# AE402FA0E5597BE0_CM55_HP_View register map
Vendor: Alif Semiconductor; Series: E4; File version: 1.0
CPU: CM55 r1p0, selectable endian, MPU, FPU, double-precision FPU, DSP, VTOR, 8 interrupt priority bits, 1 SAU regions
Registers are 32-bit, read-write, reset 0x0 unless marked. A register's access mark holds for its fields unless they carry their own. Offsets are from the block's base; [hi:lo] are bit positions; {n}, {i} and the like mark numbered series.

## JPEG
Base 0x49044000
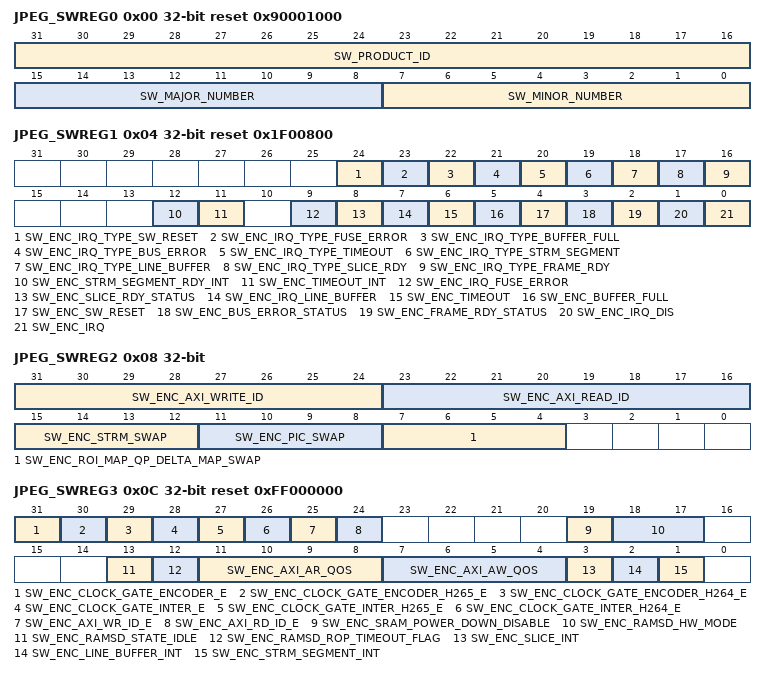
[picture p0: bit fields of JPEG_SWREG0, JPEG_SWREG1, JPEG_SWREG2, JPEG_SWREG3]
0x00 JPEG_SWREG0 ro reset 0x90001000 — swreg0 register
  [31:16] SW_PRODUCT_ID — Product ID
  [15:8] SW_MAJOR_NUMBER — Major number
  [7:0] SW_MINOR_NUMBER — Minor number
0x04 JPEG_SWREG1 reset 0x1F00800 — swreg1 register
  [24] SW_ENC_IRQ_TYPE_SW_RESET — Irq type sw reset mask.0=normal interruption. 1=abnormal interruption
  [23] SW_ENC_IRQ_TYPE_FUSE_ERROR — Irq type fuse error mask.0=normal interruption. 1=abnormal interruption
  [22] SW_ENC_IRQ_TYPE_BUFFER_FULL — Irq type fuse buffer full mask.0=normal interruption. 1=abnormal interruption
  [21] SW_ENC_IRQ_TYPE_BUS_ERROR — Irq type bus error mask.0=normal interruption. 1=abnormal interruption
  [20] SW_ENC_IRQ_TYPE_TIMEOUT — Irq type timeout mask. 0=normal interruption. 1=abnormal interruption
  [19] SW_ENC_IRQ_TYPE_STRM_SEGMENT — Irq type stream segment mask. 0=normal interruption. 1=abnormal interruption.
  [18] SW_ENC_IRQ_TYPE_LINE_BUFFER — Irq type line buffer mask. 0=normal interruption. 1=abnormal interruption.
  [17] SW_ENC_IRQ_TYPE_SLICE_RDY — Irq type slice ready mask. 0=normal interruption. 1=abnormal interruption.
  [16] SW_ENC_IRQ_TYPE_FRAME_RDY — Irq type frame ready mask. 0=normal interruption. 1=abnormal interruption.
  [12] SW_ENC_STRM_SEGMENT_RDY_INT — Output stream segment IRQ. When high stream segment requests an interrupt. SW will reset this after interrupt is handled. It is clear by writing 1.
  [11] SW_ENC_TIMEOUT_INT — enable timeout interrupt when 1
  [9] SW_ENC_IRQ_FUSE_ERROR — Interrupt Interrupt status bit encoder. When this bit is high encoder has a FUSE error. SW try to setup feature but HW miss the feature set. It is clear by writing 1.
  [8] SW_ENC_SLICE_RDY_STATUS — Interrupt status bit encoder. When this bit is high encoder has encoded a slice. It is clear by writing 1.
  [7] SW_ENC_IRQ_LINE_BUFFER — Interrupt status bit encoder linebuffer empty. When setting. Encoder has finished encoding input buffers. It is clear by writing 1.
  [6] SW_ENC_TIMEOUT — Interrupt status bit encoder timeout. When high the encoder has been idling for too long. Possible only if timeout interrupt is enabled. It is clear by writing 1.
  [5] SW_ENC_BUFFER_FULL — IRQ buffer full status bit. bufferFullInterrupt. It is clear by writing 1.
  [4] SW_ENC_SW_RESET — IRQ SW reset status bit. It is clear by writing 1.
  [3] SW_ENC_BUS_ERROR_STATUS — Interrupt status bit bus. Error response from bus. It is clear by writing 1.
  [2] SW_ENC_FRAME_RDY_STATUS — Interrupt status bit encoder. When this bit is high encoder has encoded a picture. It is clear by writing 1.
  [1] SW_ENC_IRQ_DIS — Encoder IRQ disable. When high there are no interrupts concerning encoder from HW. Polling must be used to see the interrupt statuses.
  [0] SW_ENC_IRQ — Encoder IRQ. When high encoder requests an interrupt. SW will reset this after interrupt is handled. It is clear by writing 1.
0x08 JPEG_SWREG2 — swreg2 register
  [31:24] SW_ENC_AXI_WRITE_ID — AXI Write ID
  [23:16] SW_ENC_AXI_READ_ID — AXI Read ID
  [15:12] SW_ENC_STRM_SWAP — byte swap config for output stream data.4 Bit byte order vector to control byte locations inside HW internal 128 bit data vector. For 64 and 32 bit external bus widths the data is first gathered to 128 bit width and then bytes swapped accordingly
  [11:8] SW_ENC_PIC_SWAP — Byte swap configuration for picture data (encoder input)
  [7:4] SW_ENC_ROI_MAP_QP_DELTA_MAP_SWAP — Byte swap configuration for qp delta of ROI map (include jpeg roimap)
0x0C JPEG_SWREG3 reset 0xFF000000 — swreg3 register
  [31] SW_ENC_CLOCK_GATE_ENCODER_E — ASIC encoder clock gating control. 0=clock always on. 1=hardware clock gating control
  [30] SW_ENC_CLOCK_GATE_ENCODER_H265_E — ASIC encoder clock gating control for h265. 0=clock always on. 1=hardware clock gating control
  [29] SW_ENC_CLOCK_GATE_ENCODER_H264_E — ASIC encoder clock gating control for h264. 0=clock always on. 1=hardware clock gating control
  [28] SW_ENC_CLOCK_GATE_INTER_E — ASIC inter clock gating control. 0=clock always on. 1=hardware clock gating control
  [27] SW_ENC_CLOCK_GATE_INTER_H265_E — ASIC inter clock gating control for h265. 0=clock always on. 1=hardware clock gating control
  [26] SW_ENC_CLOCK_GATE_INTER_H264_E — ASIC inter clock gating control for h264. 0=clock always on. 1=hardware clock gating control
  [25] SW_ENC_AXI_WR_ID_E — axi write enable 0=disable. 1=enable.
  [24] SW_ENC_AXI_RD_ID_E — axi read enable 0=disable. 1=enable.
  [19] SW_ENC_SRAM_POWER_DOWN_DISABLE — SRAM power down mode disable
    1=SRAM power always on; 0=go into power down mode when clock is gated
  [18:17] SW_ENC_RAMSD_HW_MODE — SRAM SD HW controlled mode
  [13] SW_ENC_RAMSD_STATE_IDLE ro — SRAM SD process idle state 0=some srams are in the sd process. 1=all sram have completed sd process
  [12] SW_ENC_RAMSD_ROP_TIMEOUT_FLAG — Flags the timeout status of the sram SD_ROP signal.0=the sram SD_ROP signal has not timed out.1=the sram SD_ROP signal has timed out
  [11:8] SW_ENC_AXI_AR_QOS — AXI Qos identifier sent on the read address channel for read transaction
  [7:4] SW_ENC_AXI_AW_QOS — AXI Qos identifier sent on the write address channel for write transaction
  [3] SW_ENC_SLICE_INT — enable slice interrupt when 1
  [2] SW_ENC_LINE_BUFFER_INT — enable line buffer interrupt when 1
  [1] SW_ENC_STRM_SEGMENT_INT — enable stream segment interrupt when 1
0x10 JPEG_SWREG4 — swreg4 register
  [31:29] SW_ENC_MODE — Encoding mode. streamType.1=hevc. 2=h264. 3=av1. 4=jpeg. 5=Reserved. 6=cutree. 7=vp9
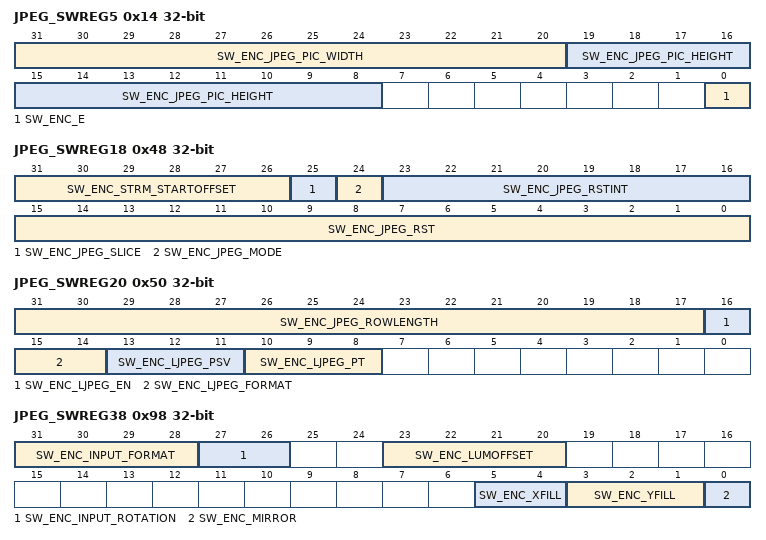
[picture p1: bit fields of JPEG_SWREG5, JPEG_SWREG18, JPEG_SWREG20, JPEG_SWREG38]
0x14 JPEG_SWREG5 — swreg5 register
  [31:20] SW_ENC_JPEG_PIC_WIDTH — Encoded jpeg width. jpgLumWidth(unit 8 pixels)
  [19:8] SW_ENC_JPEG_PIC_HEIGHT — Encoded jpeg height. jpgLumHeight(unit 8 pixels):Max width x height is 16384 x 16384
  [0] SW_ENC_E — encoder enable. Setting this bit high will start the encoding operation. HW will reset this when picture is processed or bus error or timeout interrupt is given.
0x20 JPEG_SWREG8 — swreg8 register
  [31:0] SW_ENC_OUTPUT_STRM_BASE — stream output buffer0 base address
0x24 JPEG_SWREG9 — swreg9 register
  [31:0] SW_ENC_OUTPUT_STRM_BUFFER_LIMIT — Stream buffer0 limit / Output stream size (bytes). If buffer0 limit is reached and sw_enc_HWStreamBufChain=0 buffer_full_IRQ will be generated. Output stream size will be updated here when a slice or frame is finished
0x30 JPEG_SWREG12 — swreg12 register
  [31:0] SW_ENC_INPUT_Y_BASE — input image lum base address
0x34 JPEG_SWREG13 — swreg13 register
  [31:0] SW_ENC_INPUT_CB_BASE — input image cb base address
0x38 JPEG_SWREG14 — swreg14 register
  [31:0] SW_ENC_INPUT_CR_BASE — input image cr base address
0x48 JPEG_SWREG18 — swreg18 register
  [31:26] SW_ENC_STRM_STARTOFFSET — Stream start offset = amount of StrmHdrRem (bits) [0..63]
  [25] SW_ENC_JPEG_SLICE — JPEG slice enable. 0=picture ends with EOI. 1=slice ends with RST
  [24] SW_ENC_JPEG_MODE — JPEG mode. 0=4:2:0 (4lum+2chr blocks/MCU). 1=4:2:2 (2lum+2chr blocks/MCU)
  [23:16] SW_ENC_JPEG_RSTINT — JPEG restart marker interval when slices are disabled (mb rows) [0..255]
  [15:0] SW_ENC_JPEG_RST — JPEG restart marker for first RST. incremented by HW for next RST
0x4C JPEG_SWREG19 — swreg19 register
  [31:0] SW_ENC_STRM_HDRREM1 — Stream header remainder bits MSB (MSB aligned)
0x50 JPEG_SWREG20 — swreg20 register
  [31:17] SW_ENC_JPEG_ROWLENGTH — JPEG Input luminance row length. jpgLumWidthSrc (pixels) [96..16384]
  [16] SW_ENC_LJPEG_EN — JPEG enable lossless JPEG with Huffman coding
  [15:14] SW_ENC_LJPEG_FORMAT — JPEG CodingMode 0:420 1:422 2:lumaonly
  [13:11] SW_ENC_LJPEG_PSV — JPEG prediction selection value for lossless
  [10:8] SW_ENC_LJPEG_PT — JPEG point transform value for lossless
0x54 JPEG_SWREG21 — swreg21 register
  [31:0] SW_ENC_STRM_HDRREM2 — Stream header remainder bits LSB (MSB aligned)
0x94 JPEG_SWREG37 — swreg37 register
  [3:0] SW_ENC_CHROFFSET — Input chrominance offset (bytes) [0..15]
0x98 JPEG_SWREG38 — swreg38 register
  [31:28] SW_ENC_INPUT_FORMAT — Input image format. inputFormat. 0=YUV420P/1=YUV420SP/2=YUYV422/3=UYVY422/4=RGB565/5=RGB555/6=RGB444/7=RGB888/8=RGB101010/9=I010/10=P010/11=PACKED10BITPLANAR/12=Y0L2/13=TILE32/14=TILE16PCK4
  [27:26] SW_ENC_INPUT_ROTATION — Input image rotation. 0=disabled. 1=90 degrees right. 2=90 degrees left.3=180 degree right.
  [23:20] SW_ENC_LUMOFFSET — Input luminance offset (bytes) [0..15]
  [5:4] SW_ENC_XFILL — Overfill pixels on right edge of image div2 [0.1.2.3]
  [3:1] SW_ENC_YFILL — Overfill pixels on bottom edge of image. YFill. [0...7]
  [0] SW_ENC_MIRROR — mirror or not. [0.1]
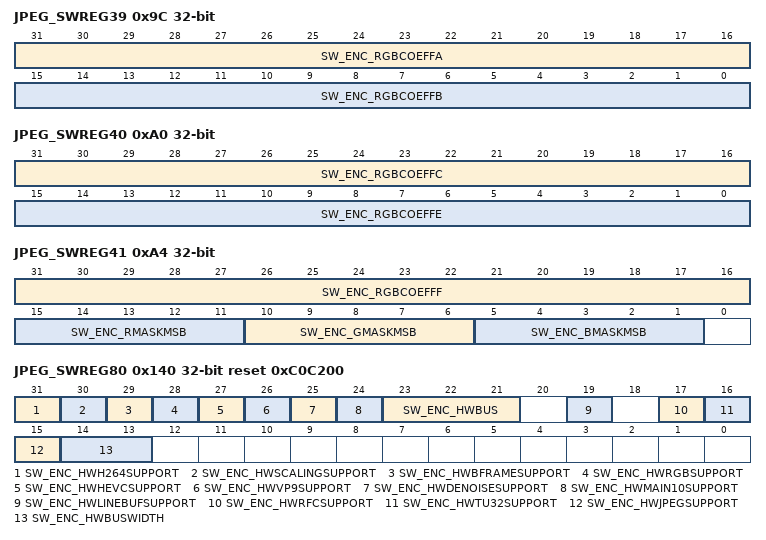
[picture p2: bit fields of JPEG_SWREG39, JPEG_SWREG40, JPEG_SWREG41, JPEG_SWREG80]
0x9C JPEG_SWREG39 — swreg39 register
  [31:16] SW_ENC_RGBCOEFFA — RGB to YUV conversion coefficient A
  [15:0] SW_ENC_RGBCOEFFB — RGB to YUV conversion coefficient B
0xA0 JPEG_SWREG40 — swreg40 register
  [31:16] SW_ENC_RGBCOEFFC — RGB to YUV conversion coefficient C
  [15:0] SW_ENC_RGBCOEFFE — RGB to YUV conversion coefficient D
0xA4 JPEG_SWREG41 — swreg41 register
  [31:16] SW_ENC_RGBCOEFFF — RGB to YUV conversion coefficient E
  [15:11] SW_ENC_RMASKMSB — RGB R-component mask MSB bit position [0..31]
  [10:6] SW_ENC_GMASKMSB — RGB G-component mask MSB bit position [0..31]
  [5:1] SW_ENC_BMASKMSB — RGB B-component mask MSB bit position [0..31]
0xB0 JPEG_SWREG44 — swreg44 register
  [1:0] SW_ENC_INPUT_FORMAT_MSB — Input image format bit[5:4]. inputFormatMsb.
0xB4 JPEG_SWREG45 — swreg45 register
  [27] SW_ENC_CHROMA_SWAP — Swap order of chroma bytes in semiplanar input format.
0xD4 JPEG_SWREG53 — swreg53 register
  [31:0] SW_ENC_INPUT_Y_BASE_MSB — input lum base address MSB
0xD8 JPEG_SWREG54 — swreg54 register
  [31:0] SW_ENC_INPUT_CB_BASE_MSB — input cb base address MSB
0xDC JPEG_SWREG55 — swreg55 register
  [31:0] SW_ENC_INPUT_CR_BASE_MSB — input cr base address MSB
0xEC JPEG_SWREG59 — swreg59 register
  [31:0] SW_ENC_OUTPUT_STRM_BASE_MSB — stream output buffer0 address MSB
0x140 JPEG_SWREG80 ro reset 0xC0C200 — swreg80 register
  [31] SW_ENC_HWH264SUPPORT — H264 encoding supported by HW. 0=not supported. 1=supported
  [30] SW_ENC_HWSCALINGSUPPORT — Down-scaling supported by HW. 0=not supported. 1=supported
  [29] SW_ENC_HWBFRAMESUPPORT — HW bframe support. 0=not support bframe. 1=support bframe
  [28] SW_ENC_HWRGBSUPPORT — RGB to YUV conversion supported by HW. 0=not supported. 1=supported
  [27] SW_ENC_HWHEVCSUPPORT — HEVC encoding supported by HW. 0=not supported. 1=supported
  [26] SW_ENC_HWVP9SUPPORT — VP9 encoding supported by HW. 0=not supported. 1=supported
  [25] SW_ENC_HWDENOISESUPPORT — denoise supported by HW. 0=not supported. 1=supported
  [24] SW_ENC_HWMAIN10SUPPORT — main10 supported by HW. 0=main8 supported. 1=main10 supported
  [23:21] SW_ENC_HWBUS — Bus connection of HW. 1=AHB. 2=OCP. 3=AXI. 4=PCI. 5=AXIAHB. 6=AXIAPB.
  [19] SW_ENC_HWLINEBUFSUPPORT — LineBuffer input mode supported by HW. 0=not supported. 1=supported
  [17] SW_ENC_HWRFCSUPPORT — Reference frame compression supported by HW. 0=not supported. 1=supported
  [16] SW_ENC_HWTU32SUPPORT — TU32 supported by HW. 0=not supported. 1=supported
  [15] SW_ENC_HWJPEGSUPPORT — JPEG encoder supported by HW. 0=not supported. 1=supported
  [14:13] SW_ENC_HWBUSWIDTH — Bus width of HW. 0=32b. 1=64b. 2=128b
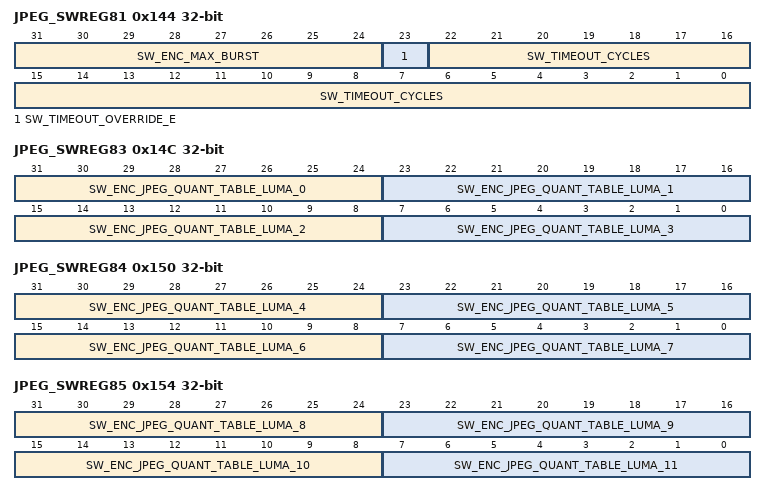
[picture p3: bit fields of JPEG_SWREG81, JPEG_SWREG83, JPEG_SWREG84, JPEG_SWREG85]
0x144 JPEG_SWREG81 — swreg81 register
  [31:24] SW_ENC_MAX_BURST — Maximum AXI burst length.Default value 0x10
  [23] SW_TIMEOUT_OVERRIDE_E — enable signal if timeout period is controlled by software Default value: 0x0
  [22:0] SW_TIMEOUT_CYCLES — timeout cycles number default value: 0x0
0x148 JPEG_SWREG82 — swreg82 register
  [31:0] SW_ENC_HW_PERFORMANCE — record hardware performance(cycles) of current picture
0x14C JPEG_SWREG83 — swreg83 register
  [31-8n:24-8n] SW_ENC_JPEG_QUANT_TABLE_LUMA_{n} (n=0..3) — jpeg quant table luma entry {n}
0x150 JPEG_SWREG84 — swreg84 register
  [63-8n:56-8n] SW_ENC_JPEG_QUANT_TABLE_LUMA_{n} (n=4..7) — jpeg quant table luma entry {n}
0x154 JPEG_SWREG85 — swreg85 register
  [95-8n:88-8n] SW_ENC_JPEG_QUANT_TABLE_LUMA_{n} (n=8..11) — jpeg quant table luma entry {n}
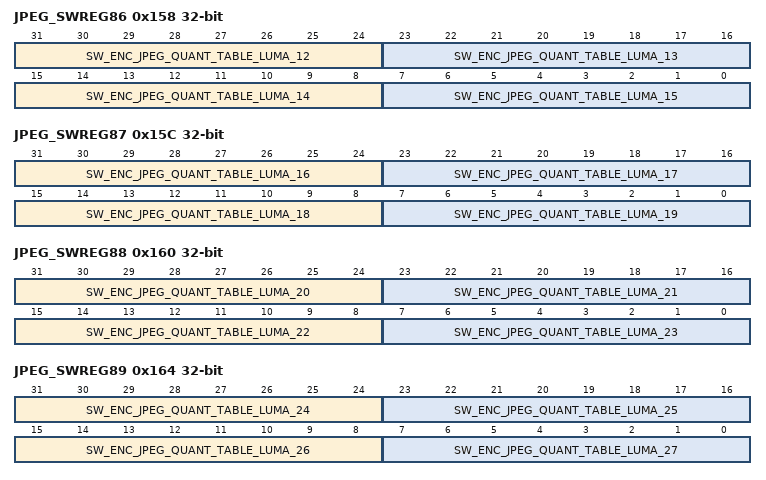
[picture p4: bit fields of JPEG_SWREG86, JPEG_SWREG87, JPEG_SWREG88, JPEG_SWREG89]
0x158 JPEG_SWREG86 — swreg86 register
  [127-8n:120-8n] SW_ENC_JPEG_QUANT_TABLE_LUMA_{n} (n=12..15) — jpeg quant table luma entry {n}
0x15C JPEG_SWREG87 — swreg87 register
  [159-8n:152-8n] SW_ENC_JPEG_QUANT_TABLE_LUMA_{n} (n=16..19) — jpeg quant table luma entry {n}
0x160 JPEG_SWREG88 — swreg88 register
  [191-8n:184-8n] SW_ENC_JPEG_QUANT_TABLE_LUMA_{n} (n=20..23) — jpeg quant table luma entry {n}
0x164 JPEG_SWREG89 — swreg89 register
  [223-8n:216-8n] SW_ENC_JPEG_QUANT_TABLE_LUMA_{n} (n=24..27) — jpeg quant table luma entry {n}
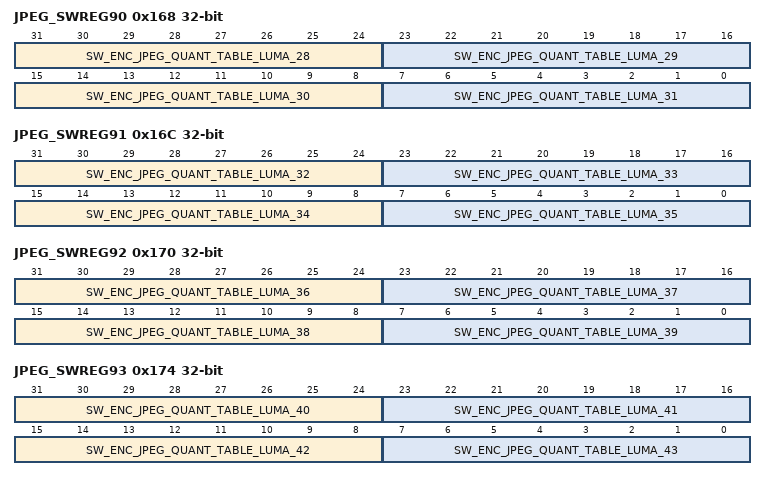
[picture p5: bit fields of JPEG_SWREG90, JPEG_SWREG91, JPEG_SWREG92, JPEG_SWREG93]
0x168 JPEG_SWREG90 — swreg90 register
  [255-8n:248-8n] SW_ENC_JPEG_QUANT_TABLE_LUMA_{n} (n=28..31) — jpeg quant table luma entry {n}
0x16C JPEG_SWREG91 — swreg91 register
  [287-8n:280-8n] SW_ENC_JPEG_QUANT_TABLE_LUMA_{n} (n=32..35) — jpeg quant table luma entry {n}
0x170 JPEG_SWREG92 — swreg92 register
  [319-8n:312-8n] SW_ENC_JPEG_QUANT_TABLE_LUMA_{n} (n=36..39) — jpeg quant table luma entry {n}
0x174 JPEG_SWREG93 — swreg93 register
  [351-8n:344-8n] SW_ENC_JPEG_QUANT_TABLE_LUMA_{n} (n=40..43) — jpeg quant table luma entry {n}
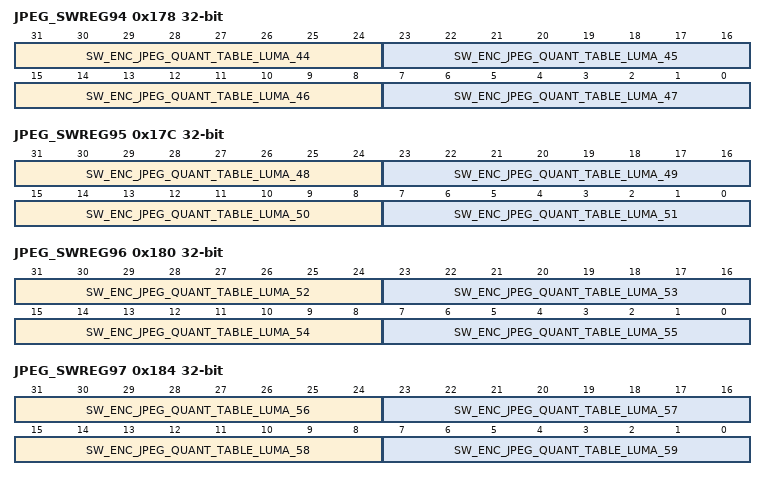
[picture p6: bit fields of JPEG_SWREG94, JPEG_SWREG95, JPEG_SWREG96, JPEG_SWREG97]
0x178 JPEG_SWREG94 — swreg94 register
  [383-8n:376-8n] SW_ENC_JPEG_QUANT_TABLE_LUMA_{n} (n=44..47) — jpeg quant table luma entry {n}
0x17C JPEG_SWREG95 — swreg95 register
  [415-8n:408-8n] SW_ENC_JPEG_QUANT_TABLE_LUMA_{n} (n=48..51) — jpeg quant table luma entry {n}
0x180 JPEG_SWREG96 — swreg96 register
  [447-8n:440-8n] SW_ENC_JPEG_QUANT_TABLE_LUMA_{n} (n=52..55) — jpeg quant table luma entry {n}
0x184 JPEG_SWREG97 — swreg97 register
  [479-8n:472-8n] SW_ENC_JPEG_QUANT_TABLE_LUMA_{n} (n=56..59) — jpeg quant table luma entry {n}
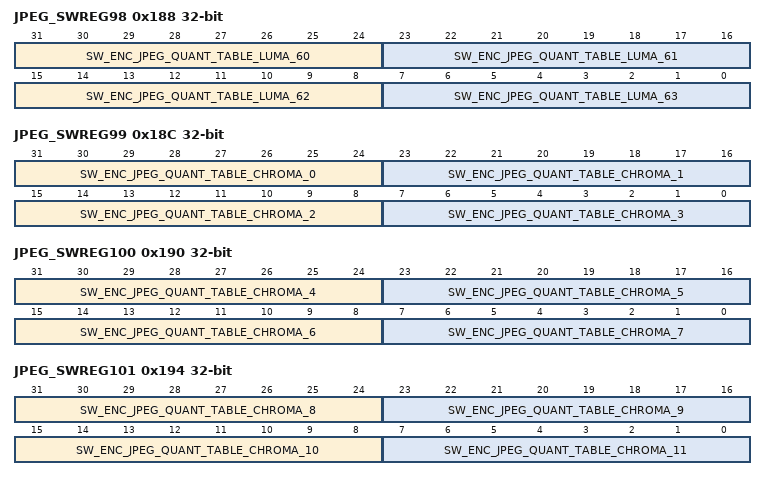
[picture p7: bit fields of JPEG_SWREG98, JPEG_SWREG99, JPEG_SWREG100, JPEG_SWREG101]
0x188 JPEG_SWREG98 — swreg98 register
  [511-8n:504-8n] SW_ENC_JPEG_QUANT_TABLE_LUMA_{n} (n=60..63) — jpeg quant table luma entry {n}
0x18C JPEG_SWREG99 — swreg99 register
  [31-8n:24-8n] SW_ENC_JPEG_QUANT_TABLE_CHROMA_{n} (n=0..3) — jpeg quant table chroma entry {n}
0x190 JPEG_SWREG100 — swreg100 register
  [63-8n:56-8n] SW_ENC_JPEG_QUANT_TABLE_CHROMA_{n} (n=4..7) — jpeg quant table chroma entry {n}
0x194 JPEG_SWREG101 — swreg101 register
  [95-8n:88-8n] SW_ENC_JPEG_QUANT_TABLE_CHROMA_{n} (n=8..11) — jpeg quant table chroma entry {n}
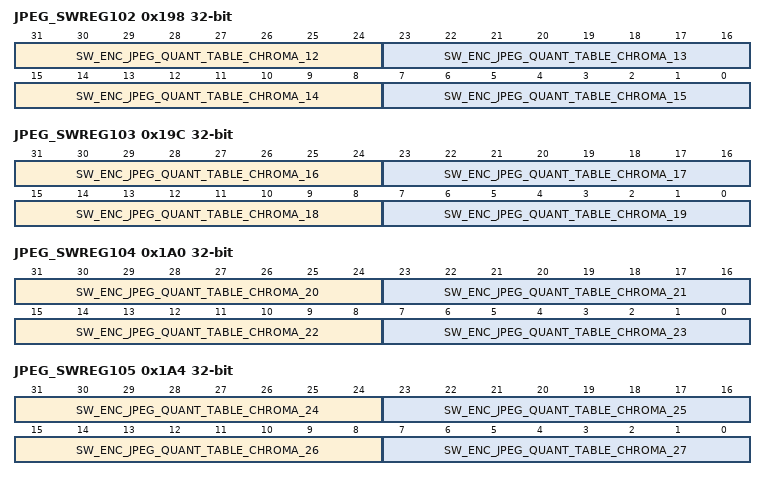
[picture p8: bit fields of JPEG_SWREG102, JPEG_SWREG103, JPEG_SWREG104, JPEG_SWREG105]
0x198 JPEG_SWREG102 — swreg102 register
  [127-8n:120-8n] SW_ENC_JPEG_QUANT_TABLE_CHROMA_{n} (n=12..15) — jpeg quant table chroma entry {n}
0x19C JPEG_SWREG103 — swreg103 register
  [159-8n:152-8n] SW_ENC_JPEG_QUANT_TABLE_CHROMA_{n} (n=16..19) — jpeg quant table chroma entry {n}
0x1A0 JPEG_SWREG104 — swreg104 register
  [191-8n:184-8n] SW_ENC_JPEG_QUANT_TABLE_CHROMA_{n} (n=20..23) — jpeg quant table chroma entry {n}
0x1A4 JPEG_SWREG105 — swreg105 register
  [223-8n:216-8n] SW_ENC_JPEG_QUANT_TABLE_CHROMA_{n} (n=24..27) — jpeg quant table chroma entry {n}
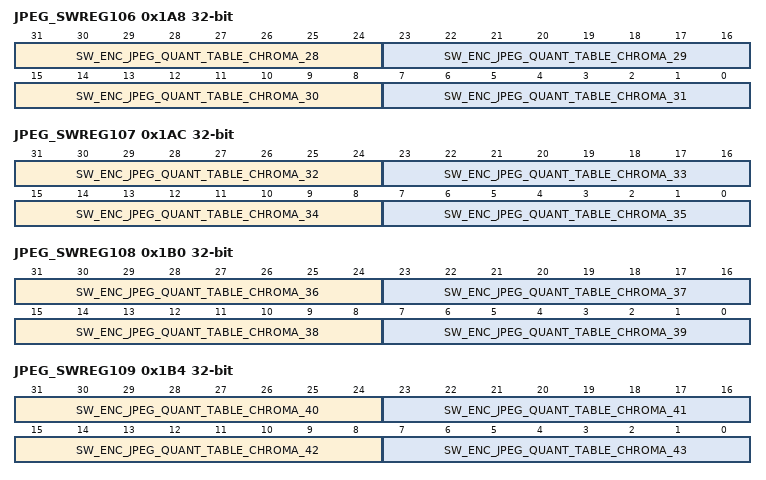
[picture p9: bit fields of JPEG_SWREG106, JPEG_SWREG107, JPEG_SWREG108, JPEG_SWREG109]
0x1A8 JPEG_SWREG106 — swreg106 register
  [255-8n:248-8n] SW_ENC_JPEG_QUANT_TABLE_CHROMA_{n} (n=28..31) — jpeg quant table chroma entry {n}
0x1AC JPEG_SWREG107 — swreg107 register
  [287-8n:280-8n] SW_ENC_JPEG_QUANT_TABLE_CHROMA_{n} (n=32..35) — jpeg quant table chroma entry {n}
0x1B0 JPEG_SWREG108 — swreg108 register
  [319-8n:312-8n] SW_ENC_JPEG_QUANT_TABLE_CHROMA_{n} (n=36..39) — jpeg quant table chroma entry {n}
0x1B4 JPEG_SWREG109 — swreg109 register
  [351-8n:344-8n] SW_ENC_JPEG_QUANT_TABLE_CHROMA_{n} (n=40..43) — jpeg quant table chroma entry {n}
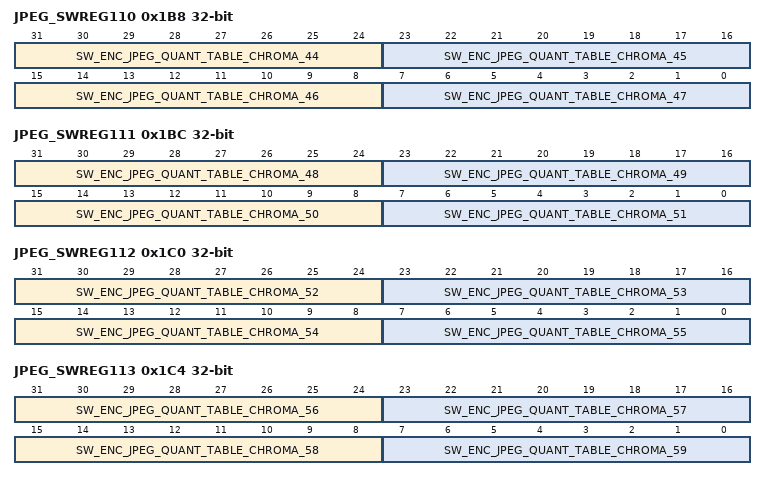
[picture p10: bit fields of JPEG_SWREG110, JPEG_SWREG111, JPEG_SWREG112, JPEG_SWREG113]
0x1B8 JPEG_SWREG110 — swreg110 register
  [383-8n:376-8n] SW_ENC_JPEG_QUANT_TABLE_CHROMA_{n} (n=44..47) — jpeg quant table chroma entry {n}
0x1BC JPEG_SWREG111 — swreg111 register
  [415-8n:408-8n] SW_ENC_JPEG_QUANT_TABLE_CHROMA_{n} (n=48..51) — jpeg quant table chroma entry {n}
0x1C0 JPEG_SWREG112 — swreg112 register
  [447-8n:440-8n] SW_ENC_JPEG_QUANT_TABLE_CHROMA_{n} (n=52..55) — jpeg quant table chroma entry {n}
0x1C4 JPEG_SWREG113 — swreg113 register
  [479-8n:472-8n] SW_ENC_JPEG_QUANT_TABLE_CHROMA_{n} (n=56..59) — jpeg quant table chroma entry {n}
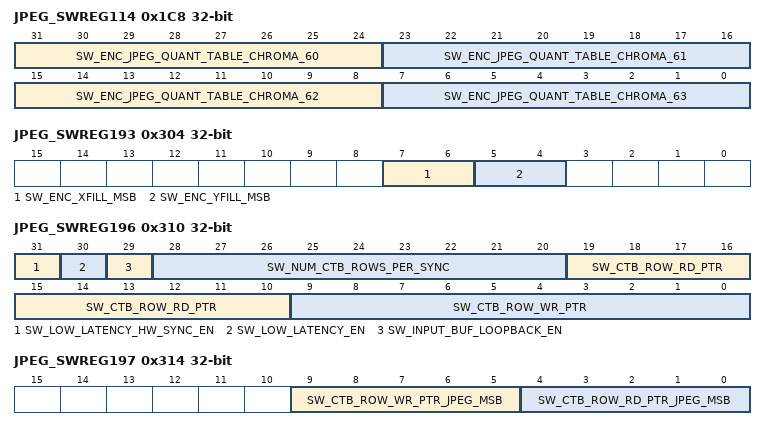
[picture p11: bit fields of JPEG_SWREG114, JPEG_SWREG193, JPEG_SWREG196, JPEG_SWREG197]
0x1C8 JPEG_SWREG114 — swreg114 register
  [511-8n:504-8n] SW_ENC_JPEG_QUANT_TABLE_CHROMA_{n} (n=60..63) — jpeg quant table chroma entry {n}
0x1FC JPEG_SWREG127 — swreg127 register
  [31:0] SW_ENC_OVERLAY_INPUT_YADDR1 — Overlay 1 input luma buffer address/OSDMap input buffer address
0x200 JPEG_SWREG128 — swreg128 register
  [31:0] SW_ENC_OVERLAY_INPUT_YADDR1_MSB — Overlay 1 input luma buffer address MSB part/OSDMap input buffer address MSB part
0x204 JPEG_SWREG129 — swreg129 register
  [31:0] SW_ENC_OVERLAY_INPUT_UADDR1 — Overlay 1 input chroma U buffer address
0x208 JPEG_SWREG130 — swreg130 register
  [31:0] SW_ENC_OVERLAY_INPUT_UADDR1_MSB — Overlay 1 input chroma U buffer address MSB part
0x20C JPEG_SWREG131 — swreg131 register
  [31:0] SW_ENC_OVERLAY_INPUT_VADDR1 — Overlay 1 input chroma V buffer address
0x210 JPEG_SWREG132 — swreg132 register
  [31:0] SW_ENC_OVERLAY_INPUT_VADDR1_MSB — Overlay 1 input chroma V buffer address MSB part
0x228 JPEG_SWREG138 — swreg138 register
  [31:0] SW_ENC_OVERLAY_INPUT_YADDR2 — Overlay 2 input luma buffer address
0x22C JPEG_SWREG139 — swreg139 register
  [31:0] SW_ENC_OVERLAY_INPUT_YADDR2_MSB — Overlay 2 input luma buffer address MSB part
0x230 JPEG_SWREG140 — swreg140 register
  [31:0] SW_ENC_OVERLAY_INPUT_UADDR2 — Overlay 2 input chroma U buffer address
0x234 JPEG_SWREG141 — swreg141 register
  [31:0] SW_ENC_OVERLAY_INPUT_UADDR2_MSB — Overlay 2 input chroma U buffer address MSB part
0x238 JPEG_SWREG142 — swreg142 register
  [31:0] SW_ENC_OVERLAY_INPUT_VADDR2 — Overlay 2 input chroma V buffer address
0x23C JPEG_SWREG143 — swreg143 register
  [31:0] SW_ENC_OVERLAY_INPUT_VADDR2_MSB — Overlay 2 input chroma V buffer address MSB part
0x240 JPEG_SWREG144 — swreg144 register
  [31:0] SW_ENC_OVERLAY_INPUT_YADDR3 — Overlay 3 input luma buffer address
0x244 JPEG_SWREG145 — swreg145 register
  [31:0] SW_ENC_OVERLAY_INPUT_YADDR3_MSB — Overlay 3 input luma buffer address MSB part
0x248 JPEG_SWREG146 — swreg146 register
  [31:0] SW_ENC_OVERLAY_INPUT_UADDR3 — Overlay 3 input chroma U buffer address
0x24C JPEG_SWREG147 — swreg147 register
  [31:0] SW_ENC_OVERLAY_INPUT_UADDR3_MSB — Overlay 3 input chroma U buffer address MSB part
0x250 JPEG_SWREG148 — swreg148 register
  [31:0] SW_ENC_OVERLAY_INPUT_VADDR3 — Overlay 3 input chroma V buffer address
0x254 JPEG_SWREG149 — swreg149 register
  [31:0] SW_ENC_OVERLAY_INPUT_VADDR3_MSB — Overlay 3 input chroma V buffer address MSB part
0x258 JPEG_SWREG150 — swreg150 register
  [31:0] SW_ENC_OVERLAY_INPUT_YADDR4 — Overlay 4 input luma buffer address
0x25C JPEG_SWREG151 — swreg151 register
  [31:0] SW_ENC_OVERLAY_INPUT_YADDR4_MSB — Overlay 4 input luma buffer address MSB part
0x260 JPEG_SWREG152 — swreg152 register
  [31:0] SW_ENC_OVERLAY_INPUT_UADDR4 — Overlay 4 input chroma U buffer address
0x264 JPEG_SWREG153 — swreg153 register
  [31:0] SW_ENC_OVERLAY_INPUT_UADDR4_MSB — Overlay 4 input chroma U buffer address MSB part
0x268 JPEG_SWREG154 — swreg154 register
  [31:0] SW_ENC_OVERLAY_INPUT_VADDR4 — Overlay 4 input chroma V buffer address
0x26C JPEG_SWREG155 — swreg155 register
  [31:0] SW_ENC_OVERLAY_INPUT_VADDR4_MSB — Overlay 4 input chroma V buffer address MSB part
0x270 JPEG_SWREG156 — swreg156 register
  [31:0] SW_ENC_OVERLAY_INPUT_YADDR5 — Overlay 5 input luma buffer address
0x274 JPEG_SWREG157 — swreg157 register
  [31:0] SW_ENC_OVERLAY_INPUT_YADDR5_MSB — Overlay 5 input luma buffer address MSB part
0x278 JPEG_SWREG158 — swreg158 register
  [31:0] SW_ENC_OVERLAY_INPUT_UADDR5 — Overlay 5 input chroma U buffer address
0x27C JPEG_SWREG159 — swreg159 register
  [31:0] SW_ENC_OVERLAY_INPUT_UADDR5_MSB — Overlay 5 input chroma U buffer address MSB part
0x280 JPEG_SWREG160 — swreg160 register
  [31:0] SW_ENC_OVERLAY_INPUT_VADDR5 — Overlay 5 input chroma V buffer address
0x284 JPEG_SWREG161 — swreg161 register
  [31:0] SW_ENC_OVERLAY_INPUT_VADDR5_MSB — Overlay 5 input chroma V buffer address MSB part
0x288 JPEG_SWREG162 — swreg162 register
  [31:0] SW_ENC_OVERLAY_INPUT_YADDR6 — Overlay 6 input luma buffer address
0x28C JPEG_SWREG163 — swreg163 register
  [31:0] SW_ENC_OVERLAY_INPUT_YADDR6_MSB — Overlay 6 input luma buffer address MSB part
0x290 JPEG_SWREG164 — swreg164 register
  [31:0] SW_ENC_OVERLAY_INPUT_UADDR6 — Overlay 6 input chroma U buffer address
0x294 JPEG_SWREG165 — swreg165 register
  [31:0] SW_ENC_OVERLAY_INPUT_UADDR6_MSB — Overlay 6 input chroma U buffer address MSB part
0x298 JPEG_SWREG166 — swreg166 register
  [31:0] SW_ENC_OVERLAY_INPUT_VADDR6 — Overlay 6 input chroma V buffer address
0x29C JPEG_SWREG167 — swreg167 register
  [31:0] SW_ENC_OVERLAY_INPUT_VADDR6_MSB — Overlay 6 input chroma V buffer address MSB part
0x2A0 JPEG_SWREG168 — swreg168 register
  [31:0] SW_ENC_OVERLAY_INPUT_YADDR7 — Overlay 7 input luma buffer address
0x2A4 JPEG_SWREG169 — swreg169 register
  [31:0] SW_ENC_OVERLAY_INPUT_YADDR7_MSB — Overlay 7 input luma buffer address MSB part
0x2B8 JPEG_SWREG174 — swreg174 register
  [31:0] SW_ENC_OVERLAY_INPUT_UADDR7 — Overlay 7 input chroma U buffer address
0x2BC JPEG_SWREG175 — swreg175 register
  [31:0] SW_ENC_OVERLAY_INPUT_UADDR7_MSB — Overlay 7 input chroma U buffer address MSB part
0x2C0 JPEG_SWREG176 — swreg176 register
  [31:0] SW_ENC_OVERLAY_INPUT_VADDR7 — Overlay 7 input chroma V buffer address
0x2C4 JPEG_SWREG177 — swreg177 register
  [31:0] SW_ENC_OVERLAY_INPUT_VADDR7_MSB — Overlay 7 input chroma V buffer address MSB part
0x2C8 JPEG_SWREG178 — swreg178 register
  [31:0] SW_ENC_OVERLAY_INPUT_YADDR8 — Overlay 8 input luma buffer address
0x2CC JPEG_SWREG179 — swreg179 register
  [31:0] SW_ENC_OVERLAY_INPUT_YADDR8_MSB — Overlay 8 input luma buffer address MSB part
0x2D0 JPEG_SWREG180 — swreg180 register
  [31:0] SW_ENC_OVERLAY_INPUT_UADDR8 — Overlay 8 input chroma U buffer address
0x2E4 JPEG_SWREG185 — swreg185 register
  [8:0] SW_TIMEOUT_CYCLES_MSB — Extend swreg81. Timeout cycles number. Bits 31:23.
0x304 JPEG_SWREG193 — swreg193 register
  [7:6] SW_ENC_XFILL_MSB — OverfillMsb pixels on right edge of image div2. XFillMsb[0.1.2.3] (bits[2:3] for H.264)
  [5:4] SW_ENC_YFILL_MSB — OverfillMsb pixels on bottom edge of image. YFillMsb [0.1.2.3] (bits[3:4] for H.264)
0x310 JPEG_SWREG196 — swreg196 register
  [31] SW_LOW_LATENCY_HW_SYNC_EN — Low Latency Hardware Interface Enable. Use hardware handshaking.
  [30] SW_LOW_LATENCY_EN — Low Latency Enable
  [29] SW_INPUT_BUF_LOOPBACK_EN — Input buffer loopback Enable
  [28:20] SW_NUM_CTB_ROWS_PER_SYNC — Number of CTB rows for every HW sync. Unit is CTB
  [19:10] SW_CTB_ROW_RD_PTR — The number of CTB rows that has been fetched from Input buffer by encoder
  [9:0] SW_CTB_ROW_WR_PTR — The number of CTB rows that has been filled into the input buffer by external application
0x314 JPEG_SWREG197 — swreg197 register
  [9:5] SW_CTB_ROW_WR_PTR_JPEG_MSB — msb of sw_ctb_row_wr_ptr for jpeg
  [4:0] SW_CTB_ROW_RD_PTR_JPEG_MSB — msb of sw_ctb_row_rd_ptr for jpeg
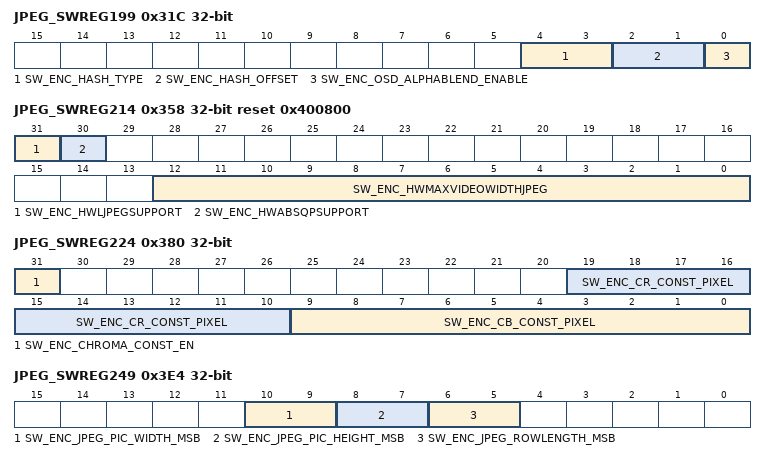
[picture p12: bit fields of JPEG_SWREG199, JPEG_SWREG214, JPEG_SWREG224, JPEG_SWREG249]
0x31C JPEG_SWREG199 — swreg199 register
  [4:3] SW_ENC_HASH_TYPE — hash type of frame data. 0=none. 1=crc32. 2=checksum32
  [2:1] SW_ENC_HASH_OFFSET — hash offset (byte offset of processed hashdata)
  [0] SW_ENC_OSD_ALPHABLEND_ENABLE — enable OSD Alpha Blending. 0=disable. 1=enable.
0x320 JPEG_SWREG200 — swreg200 register
  [31:0] SW_ENC_HASH_VAL — hash value of frame data
0x348 JPEG_SWREG210 — swreg210 register
  [31:12] SW_ENC_INPUT_LU_STRIDE — Luma stride of input frame
0x34C JPEG_SWREG211 — swreg211 register
  [31:12] SW_ENC_INPUT_CH_STRIDE — Chroma stride of input frame
0x358 JPEG_SWREG214 ro reset 0x400800 — swreg214 register
  [31] SW_ENC_HWLJPEGSUPPORT — Lossless JPEG supported by HW. 0=not supported. 1=supported
  [30] SW_ENC_HWABSQPSUPPORT — Absolute QP in ROI/ROI map supported by HW. 0=not supported. 1=supported
  [12:0] SW_ENC_HWMAXVIDEOWIDTHJPEG — Maximum video width supported by HW for JPEG encoding (unit 8 pixels)
0x35C JPEG_SWREG215 ro — swreg215 register
  [31:0] SW_ENC_TOTALARLEN — [AXI] Accumulated ARLEN+1
0x360 JPEG_SWREG216 ro — swreg216 register
  [31:0] SW_ENC_TOTALR — [AXI] RVALID & RREADY
0x364 JPEG_SWREG217 ro — swreg217 register
  [31:0] SW_ENC_TOTALAR — [AXI] ARVALID & ARREADY
0x368 JPEG_SWREG218 ro — swreg218 register
  [31:0] SW_ENC_TOTALRLAST — [AXI] RVALID & RREADY & RLAST
0x36C JPEG_SWREG219 ro — swreg219 register
  [31:0] SW_ENC_TOTALAWLEN — [AXI] Accumulated AWLEN+1
0x370 JPEG_SWREG220 ro — swreg220 register
  [31:0] SW_ENC_TOTALW — [AXI] WVALID & WREADY
0x374 JPEG_SWREG221 ro — swreg221 register
  [31:0] SW_ENC_TOTALAW — [AXI] AWVALID & AWREADY
0x378 JPEG_SWREG222 ro — swreg222 register
  [31:0] SW_ENC_TOTALWLAST — [AXI] WVALID & WREADY & WLAST
0x37C JPEG_SWREG223 ro — swreg223 register
  [31:0] SW_ENC_TOTALB — [AXI] BVALID & BREADY
0x380 JPEG_SWREG224 — swreg224 register
  [31] SW_ENC_CHROMA_CONST_EN — Force Chroma to be a constant pixel or not. 0=no. 1=yes.
  [19:10] SW_ENC_CR_CONST_PIXEL — The constant pixel of CR if sw_enc_chroma_const_en=1
  [9:0] SW_ENC_CB_CONST_PIXEL — The constant pixel of CB if sw_enc_chroma_const_en=1
0x388 JPEG_SWREG226 ro — swreg226 register
  [2] SW_ENC_HWSTREAMSEGMENTSUPPORT — Stream segment supported by HW. 0=not supported. 1=supported
0x3D8 JPEG_SWREG246 — swreg246 register
  [13:6] SW_ENC_AXI_WRITE_OUTSTANDING_NUM — AXI outstanding number of write operation
0x3E4 JPEG_SWREG249 — swreg249 register
  [10:9] SW_ENC_JPEG_PIC_WIDTH_MSB — Encoded jpeg width. jpgLumWidthMSB(unit 8 pixels)
  [8:7] SW_ENC_JPEG_PIC_HEIGHT_MSB — Encoded jpeg height. jpgLumHeightMSB(unit 8 pixels):Max width x height is 24Kx24K
  [6:5] SW_ENC_JPEG_ROWLENGTH_MSB — JPEG Input luminance row length. jpgLumWidthSrcMSB (pixels) [96..16384]
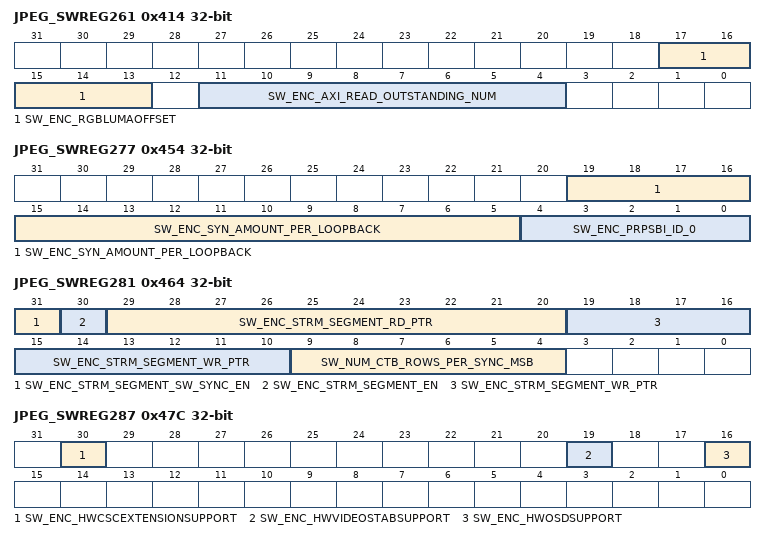
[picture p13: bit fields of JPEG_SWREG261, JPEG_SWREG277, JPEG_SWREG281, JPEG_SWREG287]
0x414 JPEG_SWREG261 — swreg261 register
  [17:13] SW_ENC_RGBLUMAOFFSET — RGB to YUV conversion luma offset
  [11:4] SW_ENC_AXI_READ_OUTSTANDING_NUM — AXI outstanding number of read operation
0x454 JPEG_SWREG277 — swreg277 register
  [19:5] SW_ENC_SYN_AMOUNT_PER_LOOPBACK — Handshake sync amount for every loopback
  [4:0] SW_ENC_PRPSBI_ID_0 — id of prp sbi
0x458 JPEG_SWREG278 — swreg278 register
  [31:0] SW_ENC_OUTPUT_STRM_BUF1_BASE — stream output buffer1 base address. Only valid if sw_enc_HWStreamBufChain=1.
0x45C JPEG_SWREG279 — swreg279 register
  [31:0] SW_ENC_OUTPUT_STRM_BUF1_BASE_MSB — stream output buffer1 address MSB
0x460 JPEG_SWREG280 — swreg280 register
  [31:0] SW_ENC_OUTPUT_STRM_BUFFER1_LIMIT — Stream buffer1 limit size (bytes). Only valid if sw_enc_HWStreamBufChain=1. If buffer1 limit is reached buffer_full_IRQ will be generated.
0x464 JPEG_SWREG281 — swreg281 register
  [31] SW_ENC_STRM_SEGMENT_SW_SYNC_EN — Stream segment software handshake enable. Set 0 will disable this handshake
  [30] SW_ENC_STRM_SEGMENT_EN — Stream segment function enable
  [29:20] SW_ENC_STRM_SEGMENT_RD_PTR — the number of segments that have been read out from output buffer
  [19:10] SW_ENC_STRM_SEGMENT_WR_PTR — the number of segments that have been filled into the output buffer
  [9:4] SW_NUM_CTB_ROWS_PER_SYNC_MSB — Number MSB of CTB rows for every HW sync. Bit[14:9]. Unit is CTB
0x47C JPEG_SWREG287 ro — swreg287 register
  [30] SW_ENC_HWCSCEXTENSIONSUPPORT — RGB to YUV conversion extension. 0=not supported. 1=supported
  [19] SW_ENC_HWVIDEOSTABSUPPORT — HW supports video stabilization or not. 0=not supported. 1=supported
  [16] SW_ENC_HWOSDSUPPORT — HW OSD supported by HW. 0=not supported. 1=supported
0x480 JPEG_SWREG288 — swreg288 register
  [9:0] SW_ENC_PRPSBI_WRSEGINITNUM — segment init num of prp sbi write before encoding a new frame
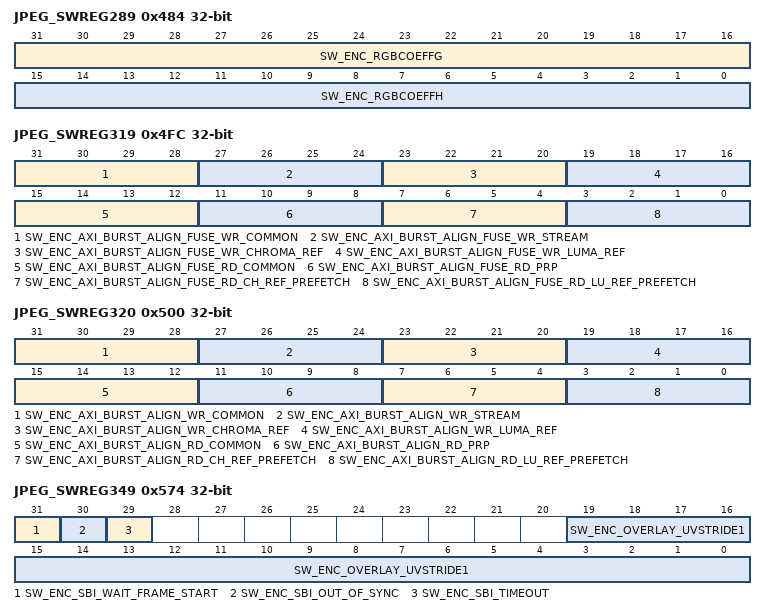
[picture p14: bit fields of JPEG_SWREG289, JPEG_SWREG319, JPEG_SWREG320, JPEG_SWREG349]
0x484 JPEG_SWREG289 — swreg289 register
  [31:16] SW_ENC_RGBCOEFFG — RGB to YUV conversion coefficient G
  [15:0] SW_ENC_RGBCOEFFH — RGB to YUV conversion coefficient H
0x488 JPEG_SWREG290 ro — swreg290 register
  [31:0] SW_ENC_TOTALARLEN2 — [AXI2] Accumulated ARLEN+1
0x48C JPEG_SWREG291 ro — swreg291 register
  [31:0] SW_ENC_TOTALR2 — [AXI2] RVALID & RREADY
0x490 JPEG_SWREG292 ro — swreg292 register
  [31:0] SW_ENC_TOTALAR2 — [AXI2] ARVALID & ARREADY
0x494 JPEG_SWREG293 ro — swreg293 register
  [31:0] SW_ENC_TOTALRLAST2 — [AXI2] RVALID & RREADY & RLAST
0x498 JPEG_SWREG294 ro — swreg294 register
  [31:0] SW_ENC_TOTALAWLEN2 — [AXI2] Accumulated AWLEN+1
0x49C JPEG_SWREG295 ro — swreg295 register
  [31:0] SW_ENC_TOTALW2 — [AXI2] WVALID & WREADY
0x4A0 JPEG_SWREG296 ro — swreg296 register
  [31:0] SW_ENC_TOTALAW2 — [AXI2] AWVALID & AWREADY
0x4A4 JPEG_SWREG297 ro — swreg297 register
  [31:0] SW_ENC_TOTALWLAST2 — [AXI2] WVALID & WREADY & WLAST
0x4A8 JPEG_SWREG298 ro — swreg298 register
  [31:0] SW_ENC_TOTALB2 — [AXI2] BVALID & BREADY
0x4D0 JPEG_SWREG308 ro — swreg308 register
  [31:0] SW_ENC_AXI_STRM_WRITE_PENDING — EMC stream AXI write pending
0x4DC JPEG_SWREG311 ro — swreg311 register
  [31:0] SW_ENC_AXI_PRP_READ_PENDING — Prp AXI read pending
0x4F4 JPEG_SWREG317 ro — swreg317 register
  [31:0] SW_ENC_AXI_TOTAL_PENDING — Total AXI bus pending
0x4FC JPEG_SWREG319 ro — swreg319 register
  [31:28] SW_ENC_AXI_BURST_ALIGN_FUSE_WR_COMMON — AXI burst align wr common fuse setting
  [27:24] SW_ENC_AXI_BURST_ALIGN_FUSE_WR_STREAM — AXI burst align wr stream fuse setting
  [23:20] SW_ENC_AXI_BURST_ALIGN_FUSE_WR_CHROMA_REF — AXI burst align wr chroma ref fuse setting
  [19:16] SW_ENC_AXI_BURST_ALIGN_FUSE_WR_LUMA_REF — AXI burst align wr luma ref fuse setting
  [15:12] SW_ENC_AXI_BURST_ALIGN_FUSE_RD_COMMON — AXI burst align rd common fuse setting
  [11:8] SW_ENC_AXI_BURST_ALIGN_FUSE_RD_PRP — AXI burst align rd prp fuse setting
  [7:4] SW_ENC_AXI_BURST_ALIGN_FUSE_RD_CH_REF_PREFETCH — AXI burst align rd ch ref prefetch fuse setting
  [3:0] SW_ENC_AXI_BURST_ALIGN_FUSE_RD_LU_REF_PREFETCH — AXI burst align rd lu ref prefetch fuse setting
0x500 JPEG_SWREG320 — swreg320 register
  [31:28] SW_ENC_AXI_BURST_ALIGN_WR_COMMON — AXI burst align wr common
  [27:24] SW_ENC_AXI_BURST_ALIGN_WR_STREAM — AXI burst align wr stream
  [23:20] SW_ENC_AXI_BURST_ALIGN_WR_CHROMA_REF — AXI burst align wr chroma ref
  [19:16] SW_ENC_AXI_BURST_ALIGN_WR_LUMA_REF — AXI burst align wr luma ref
  [15:12] SW_ENC_AXI_BURST_ALIGN_RD_COMMON — AXI burst align rd common
  [11:8] SW_ENC_AXI_BURST_ALIGN_RD_PRP — AXI burst align rd prp
  [7:4] SW_ENC_AXI_BURST_ALIGN_RD_CH_REF_PREFETCH — AXI burst align rd ch ref prefetch
  [3:0] SW_ENC_AXI_BURST_ALIGN_RD_LU_REF_PREFETCH — AXI burst align rd lu ref prefetch
0x574 JPEG_SWREG349 — swreg349 register
  [31] SW_ENC_SBI_WAIT_FRAME_START — sbi wait for data ready before each frame start
  [30] SW_ENC_SBI_OUT_OF_SYNC — sbi out of sync indication bit
  [29] SW_ENC_SBI_TIMEOUT — sbi timeout indication bit
  [19:0] SW_ENC_OVERLAY_UVSTRIDE1 — Overlay 1 chroma stride
0x6B8 JPEG_SWREG430 ro reset 0xC00000 — swreg430 register
  [29] SW_ENC_HWJPEGROIMAPSUPPORT — HW Jpeg support RoiMap. 0=not supported. 1=supported.
  [28] SW_ENC_HWBACKGROUNDDETSUPPORT — HW Back ground detection support. 0=not supported. 1=supported.
  [22] SW_ENC_HWNVFORMATONLYSUPPORT — HW only support nv input format. 0=support all input format. 1=only support nv input format
  [17] SW_ENC_HWPRPSBISUPPORT — PSNR calculation supported by HW. 0=not supported. 1=supported
0x7D0 JPEG_SWREG500 ro — swreg500 register
  [29:20] SW_ENC_REQUEST_SEG_NUM_2 — seg num of successful handshaking request channel 2
  [19:10] SW_ENC_REQUEST_SEG_NUM_1 — seg num of successful handshaking request channel 1
  [9:0] SW_ENC_REQUEST_SEG_NUM_0 — seg num of successful handshaking request channel 0
0x7D4 JPEG_SWREG501 ro — swreg501 register
  [29:20] SW_ENC_UPDATE_SEG_NUM_2 — seg num of successful handshaking update channel 2
  [19:10] SW_ENC_UPDATE_SEG_NUM_1 — seg num of successful handshaking update channel 1
  [9:0] SW_ENC_UPDATE_SEG_NUM_0 — seg num of successful handshaking update channel 0
0x7F4 JPEG_SWREG509 ro reset 0x2090 — swreg509 register
  [31:0] SW_ENC_BUILD_ID — Build ID
0x7F8 JPEG_SWREG510 ro reset 0x1234567 — swreg510 register
  [31:0] SW_ENC_BUILD_CL — Build CL
0x7FC JPEG_SWREG511 ro reset 0x20170420 — swreg511 register
  [31:0] SW_ENC_BUILD_DATE — Build Date
